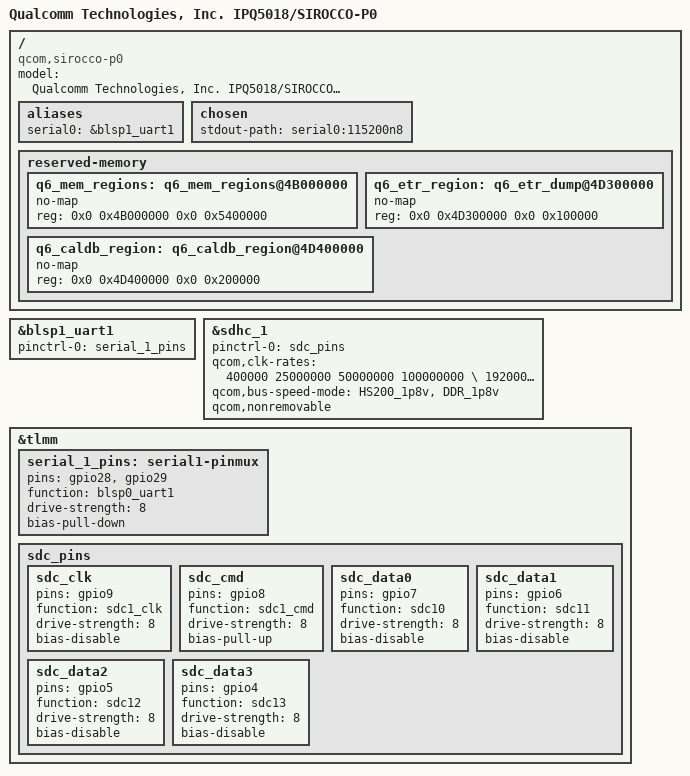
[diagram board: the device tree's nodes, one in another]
/* Copyright (c) 2018-2021, The Linux Foundation. All rights reserved.
 *
 * Permission to use, copy, modify, and/or distribute this software for any
 * purpose with or without fee is hereby granted, provided that the above
 * copyright notice and this permission notice appear in all copies.
 *
 * THE SOFTWARE IS PROVIDED "AS IS" AND THE AUTHOR DISCLAIMS ALL WARRANTIES
 * WITH REGARD TO THIS SOFTWARE INCLUDING ALL IMPLIED WARRANTIES OF
 * MERCHANTABILITY AND FITNESS. IN NO EVENT SHALL THE AUTHOR BE LIABLE FOR
 * ANY SPECIAL, DIRECT, INDIRECT, OR CONSEQUENTIAL DAMAGES OR ANY DAMAGES
 * WHATSOEVER RESULTING FROM LOSS OF USE, DATA OR PROFITS, WHETHER IN AN
 * ACTION OF CONTRACT, NEGLIGENCE OR OTHER TORTIOUS ACTION, ARISING OUT OF
 * OR IN CONNECTION WITH THE USE OR PERFORMANCE OF THIS SOFTWARE.
 */

/dts-v1/;

#include "ipq5018.dtsi"

/ {
	model = "Qualcomm Technologies, Inc. IPQ5018/SIROCCO-P0";
	compatible = "qcom,sirocco-p0", "qcom,ipq5018";

	aliases {
		serial0 = &blsp1_uart1;
	};

	chosen {
		stdout-path = "serial0:115200n8";
	};

	reserved-memory {
		q6_mem_regions: q6_mem_regions@4B000000 {
			no-map;
			reg = <0x0 0x4B000000 0x0 0x5400000>;
		};

		q6_etr_region: q6_etr_dump@4D300000 {
			no-map;
			reg = <0x0 0x4D300000 0x0 0x100000>;
		};

		q6_caldb_region: q6_caldb_region@4D400000 {
			no-map;
			reg = <0x0 0x4D400000 0x0 0x200000>;
		};
	};
};

&blsp1_uart1 {
	pinctrl-0 = <&serial_1_pins>;
	pinctrl-names = "default";
	status = "ok";
};

&sdhc_1 {
	pinctrl-0 = <&sdc_pins>;
	pinctrl-names = "default";
	qcom,clk-rates = <400000 25000000 50000000 100000000 \
			  192000000 384000000>;
	qcom,bus-speed-mode = "HS200_1p8v", "DDR_1p8v";
	qcom,nonremovable;
	status = "ok";
};

&tlmm {
	serial_1_pins: serial1-pinmux {
		pins = "gpio28", "gpio29";
		function = "blsp0_uart1";
		drive-strength = <8>;
		bias-pull-down;
	};

	sdc_pins: sdc_pins {
		sdc_clk {
			pins = "gpio9";
			function = "sdc1_clk";
			drive-strength = <8>;
			bias-disable;
		};
		sdc_cmd {
			pins = "gpio8";
			function = "sdc1_cmd";
			drive-strength = <8>;
			bias-pull-up;
		};
		sdc_data0 {
			pins = "gpio7";
			function = "sdc10";
			drive-strength = <8>;
			bias-disable;
		};
		sdc_data1 {
			pins = "gpio6";
			function = "sdc11";
			drive-strength = <8>;
			bias-disable;
		};
		sdc_data2 {
			pins = "gpio5";
			function = "sdc12";
			drive-strength = <8>;
			bias-disable;
		};
		sdc_data3 {
			pins = "gpio4";
			function = "sdc13";
			drive-strength = <8>;
			bias-disable;
		};
	};
};
